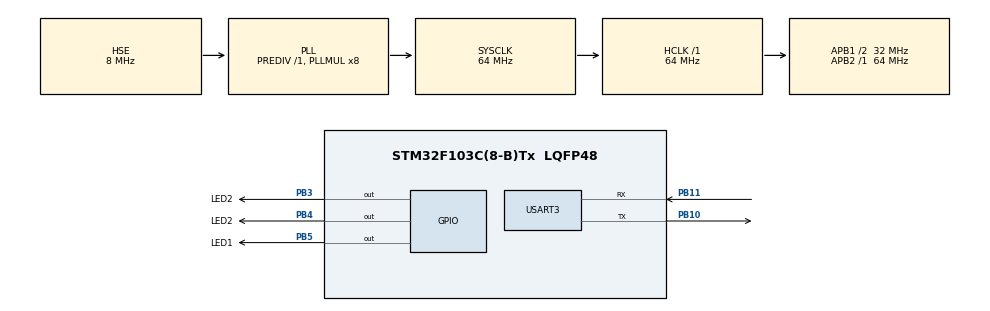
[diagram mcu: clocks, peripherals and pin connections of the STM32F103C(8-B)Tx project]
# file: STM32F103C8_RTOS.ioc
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Mcu.Family=STM32F1
Mcu.Name=STM32F103C(8-B)Tx
Mcu.Package=LQFP48
NVIC.PriorityGroup=NVIC_PRIORITYGROUP_4
NVIC.TIM2_IRQn=true\:15\:0\:false\:false\:true\:false\:true\:true
NVIC.TimeBase=TIM2_IRQn
NVIC.TimeBaseIP=TIM2
PB10.Mode=Asynchronous
PB10.Signal=USART3_TX
PB11.Mode=Asynchronous
PB11.Signal=USART3_RX
PB3.GPIO_Label=LED2
PB3.Signal=GPIO_Output
PB4.GPIO_Label=LED2
PB4.Signal=GPIO_Output
PB5.GPIO_Label=LED1
PB5.Signal=GPIO_Output
PD0-OSC_IN.Mode=HSE-External-Oscillator
PD0-OSC_IN.Signal=RCC_OSC_IN
PD1-OSC_OUT.Mode=HSE-External-Oscillator
PD1-OSC_OUT.Signal=RCC_OSC_OUT
ProjectManager.HeapSize=0x200
ProjectManager.StackSize=0x400
ProjectManager.TargetToolchain=STM32CubeIDE
RCC.AHBFreq_Value=64000000
RCC.APB1CLKDivider=RCC_HCLK_DIV2
RCC.APB1Freq_Value=32000000
RCC.APB1TimFreq_Value=64000000
RCC.APB2Freq_Value=64000000
RCC.APB2TimFreq_Value=64000000
RCC.HCLKFreq_Value=64000000
RCC.PLLMUL=RCC_PLL_MUL8
RCC.PLLSourceVirtual=RCC_PLLSOURCE_HSE
RCC.SYSCLKFreq_VALUE=64000000
RCC.SYSCLKSource=RCC_SYSCLKSOURCE_PLLCLK
RCC.USBFreq_Value=64000000
USART3.VirtualMode=VM_ASYNC
VP_SYS_VS_ND.Mode=No_Debug
VP_SYS_VS_tim2.Mode=TIM2
board=custom

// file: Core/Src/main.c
/* USER CODE BEGIN Header */
/**
  ******************************************************************************
  * @file           : main.c
  * @brief          : Main program body
  ******************************************************************************
  * @attention
  *
  * Copyright (c) 2024 STMicroelectronics.
  * All rights reserved.
  *
  * This software is licensed under terms that can be found in the LICENSE file
  * in the root directory of this software component.
  * If no LICENSE file comes with this software, it is provided AS-IS.
  *
  ******************************************************************************
  */
/* USER CODE END Header */
#include "main.h"

/* USER CODE BEGIN PD */
#define DWT_CTRL (*(volatile uint32_t *) 0xE0001000)
/* USER CODE END PD */

UART_HandleTypeDef huart3;

void SystemClock_Config(void);
static void MX_GPIO_Init(void);
static void MX_USART3_UART_Init(void);

int main(void)
{

  /* MCU Configuration--------------------------------------------------------*/

  /* Reset of all peripherals, Initializes the Flash interface and the Systick. */
  HAL_Init();

  /* Configure the system clock */
  SystemClock_Config();

  /* Initialize all configured peripherals */
  MX_GPIO_Init();
  MX_USART3_UART_Init();
  /* USER CODE BEGIN 2 */

  //enable the cycle counter (CYCCNT register)
  DWT_CTRL |= (1<<0);

  /* USER CODE END 2 */

  /* Infinite loop */
  while (1)
  {

  }
}

void SystemClock_Config(void)
{
  RCC_OscInitTypeDef RCC_OscInitStruct = {0};
  RCC_ClkInitTypeDef RCC_ClkInitStruct = {0};

  /** Initializes the RCC Oscillators according to the specified parameters
  * in the RCC_OscInitTypeDef structure.
  */
  RCC_OscInitStruct.OscillatorType = RCC_OSCILLATORTYPE_HSE;
  RCC_OscInitStruct.HSEState = RCC_HSE_ON;
  RCC_OscInitStruct.HSEPredivValue = RCC_HSE_PREDIV_DIV1;
  RCC_OscInitStruct.HSIState = RCC_HSI_ON;
  RCC_OscInitStruct.PLL.PLLState = RCC_PLL_ON;
  RCC_OscInitStruct.PLL.PLLSource = RCC_PLLSOURCE_HSE;
  RCC_OscInitStruct.PLL.PLLMUL = RCC_PLL_MUL8;
  if (HAL_RCC_OscConfig(&RCC_OscInitStruct) != HAL_OK)
  {
    Error_Handler();
  }

  /** Initializes the CPU, AHB and APB buses clocks
  */
  RCC_ClkInitStruct.ClockType = RCC_CLOCKTYPE_HCLK|RCC_CLOCKTYPE_SYSCLK
                              |RCC_CLOCKTYPE_PCLK1|RCC_CLOCKTYPE_PCLK2;
  RCC_ClkInitStruct.SYSCLKSource = RCC_SYSCLKSOURCE_PLLCLK;
  RCC_ClkInitStruct.AHBCLKDivider = RCC_SYSCLK_DIV1;
  RCC_ClkInitStruct.APB1CLKDivider = RCC_HCLK_DIV2;
  RCC_ClkInitStruct.APB2CLKDivider = RCC_HCLK_DIV1;

  if (HAL_RCC_ClockConfig(&RCC_ClkInitStruct, FLASH_LATENCY_2) != HAL_OK)
  {
    Error_Handler();
  }
}

static void MX_USART3_UART_Init(void)
{

  huart3.Instance = USART3;
  huart3.Init.BaudRate = 115200;
  huart3.Init.WordLength = UART_WORDLENGTH_8B;
  huart3.Init.StopBits = UART_STOPBITS_1;
  huart3.Init.Parity = UART_PARITY_NONE;
  huart3.Init.Mode = UART_MODE_TX_RX;
  huart3.Init.HwFlowCtl = UART_HWCONTROL_NONE;
  huart3.Init.OverSampling = UART_OVERSAMPLING_16;
  if (HAL_UART_Init(&huart3) != HAL_OK)
  {
    Error_Handler();
  }

}

static void MX_GPIO_Init(void)
{
  GPIO_InitTypeDef GPIO_InitStruct = {0};

  /* GPIO Ports Clock Enable */
  __HAL_RCC_GPIOD_CLK_ENABLE();
  __HAL_RCC_GPIOB_CLK_ENABLE();

  /*Configure GPIO pin Output Level */
  HAL_GPIO_WritePin(GPIOB, LED2_Pin|LED2B4_Pin|LED1_Pin, GPIO_PIN_RESET);

  /*Configure GPIO pins : LED2_Pin LED2B4_Pin LED1_Pin */
  GPIO_InitStruct.Pin = LED2_Pin|LED2B4_Pin|LED1_Pin;
  GPIO_InitStruct.Mode = GPIO_MODE_OUTPUT_PP;
  GPIO_InitStruct.Pull = GPIO_NOPULL;
  GPIO_InitStruct.Speed = GPIO_SPEED_FREQ_LOW;
  HAL_GPIO_Init(GPIOB, &GPIO_InitStruct);

}

void HAL_TIM_PeriodElapsedCallback(TIM_HandleTypeDef *htim)
{
  if (htim->Instance == TIM2) {
    HAL_IncTick();
  }
}

void Error_Handler(void)
{
  __disable_irq();
  while (1)
  {
  }
}
